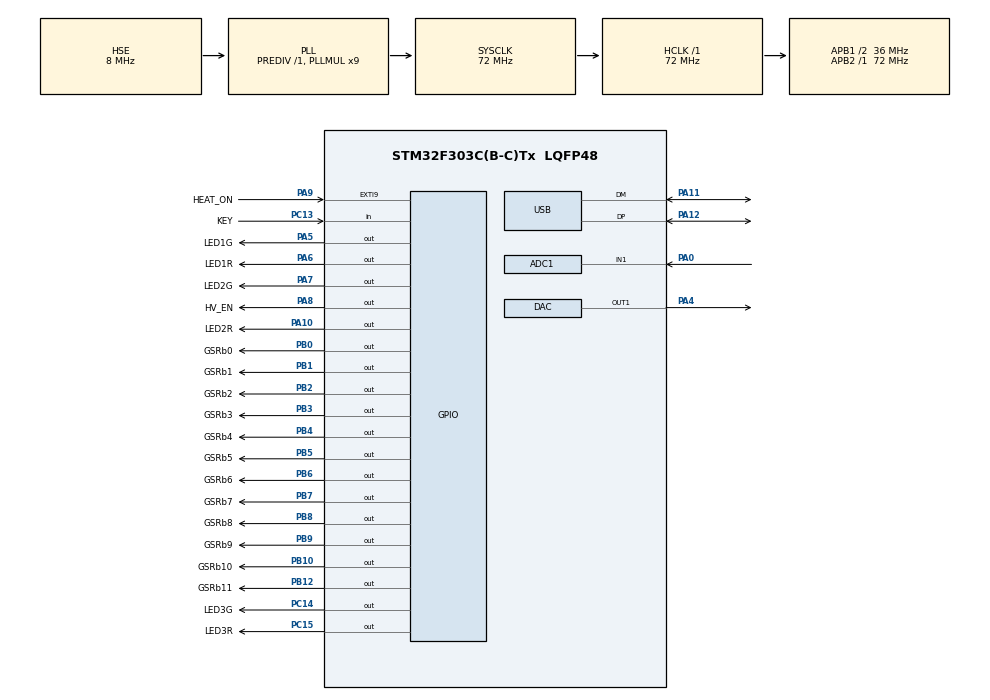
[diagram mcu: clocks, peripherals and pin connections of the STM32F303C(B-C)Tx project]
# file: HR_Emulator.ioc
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ADC1.Channel-0\#ChannelRegularConversion=ADC_CHANNEL_1
ADC1.NbrOfConversionFlag=1
ADC1.Offset-0\#ChannelRegularConversion=0
ADC1.OffsetNumber-0\#ChannelRegularConversion=ADC_OFFSET_NONE
ADC1.Rank-0\#ChannelRegularConversion=1
ADC1.SamplingTime-0\#ChannelRegularConversion=ADC_SAMPLETIME_1CYCLE_5
ADC1.SamplingTimeOPAMP-0\#ChannelRegularConversion=ADC_SAMPLETIME_4CYCLES_5
ADC1.master=1
Mcu.Family=STM32F3
Mcu.Name=STM32F303C(B-C)Tx
Mcu.Package=LQFP48
NVIC.PriorityGroup=NVIC_PRIORITYGROUP_4
PA0.Mode=IN1-Single-Ended
PA0.Signal=ADC1_IN1
PA10.GPIO_Label=LED2R
PA10.Signal=GPIO_Output
PA11.Mode=Device
PA11.Signal=USB_DM
PA12.Mode=Device
PA12.Signal=USB_DP
PA13.Mode=Serial_Wire
PA13.Signal=SYS_JTMS-SWDIO
PA14.Mode=Serial_Wire
PA14.Signal=SYS_JTCK-SWCLK
PA4.Signal=COMP_DAC1_group
PA5.GPIO_Label=LED1G
PA5.Signal=GPIO_Output
PA6.GPIO_Label=LED1R
PA6.Signal=GPIO_Output
PA7.GPIO_Label=LED2G
PA7.Signal=GPIO_Output
PA8.GPIO_Label=HV_EN
PA8.Signal=GPIO_Output
PA9.GPIO_Label=HEAT_ON
PA9.Signal=GPXTI9
PB0.GPIO_Label=GSRb0
PB0.Signal=GPIO_Output
PB1.GPIO_Label=GSRb1
PB1.Signal=GPIO_Output
PB10.GPIO_Label=GSRb10
PB10.Signal=GPIO_Output
PB12.GPIO_Label=GSRb11
PB12.Signal=GPIO_Output
PB2.GPIO_Label=GSRb2
PB2.Signal=GPIO_Output
PB3.GPIO_Label=GSRb3
PB3.Signal=GPIO_Output
PB4.GPIO_Label=GSRb4
PB4.Signal=GPIO_Output
PB5.GPIO_Label=GSRb5
PB5.Signal=GPIO_Output
PB6.GPIO_Label=GSRb6
PB6.Signal=GPIO_Output
PB7.GPIO_Label=GSRb7
PB7.Signal=GPIO_Output
PB8.GPIO_Label=GSRb8
PB8.Signal=GPIO_Output
PB9.GPIO_Label=GSRb9
PB9.Signal=GPIO_Output
PC13.GPIO_Label=KEY
PC13.Signal=GPIO_Input
PC14-OSC32_IN.GPIO_Label=LED3G
PC14-OSC32_IN.Signal=GPIO_Output
PC15-OSC32_OUT.GPIO_Label=LED3R
PC15-OSC32_OUT.Signal=GPIO_Output
PF0-OSC_IN.Mode=HSE-External-Oscillator
PF0-OSC_IN.Signal=RCC_OSC_IN
PF1-OSC_OUT.Mode=HSE-External-Oscillator
PF1-OSC_OUT.Signal=RCC_OSC_OUT
ProjectManager.HeapSize=0x200
ProjectManager.StackSize=0x400
ProjectManager.TargetToolchain=MDK-ARM V5.32
RCC.AHBFreq_Value=72000000
RCC.APB1CLKDivider=RCC_HCLK_DIV2
RCC.APB1Freq_Value=36000000
RCC.APB1TimFreq_Value=72000000
RCC.APB2Freq_Value=72000000
RCC.APB2TimFreq_Value=72000000
RCC.CortexFreq_Value=72000000
RCC.HCLKFreq_Value=72000000
RCC.HSE_VALUE=8000000
RCC.HSI_VALUE=8000000
RCC.LSE_VALUE=32768
RCC.PLLMUL=RCC_PLL_MUL9
RCC.PRESCALERUSB=RCC_USBCLKSOURCE_PLL_DIV1_5
RCC.SYSCLKFreq_VALUE=72000000
RCC.SYSCLKSourceVirtual=RCC_SYSCLKSOURCE_PLLCLK
RCC.USBFreq_Value=48000000
SH.COMP_DAC1_group.0=DAC_OUT1,DAC_OUT1
USB.low_power_enable=DISABLE
USB.lpm_enable=DISABLE
board=custom

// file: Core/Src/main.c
/* USER CODE BEGIN Header */
/**
  ******************************************************************************
  * @file           : main.c
  * @brief          : Main program body
  ******************************************************************************
  * @attention
  *
  * Copyright (c) 2026 STMicroelectronics.
  * All rights reserved.
  *
  * This software is licensed under terms that can be found in the LICENSE file
  * in the root directory of this software component.
  * If no LICENSE file comes with this software, it is provided AS-IS.
  *
  ******************************************************************************
  */
/* USER CODE END Header */
#include "main.h"
#include "adc.h"
#include "dac.h"
#include "usb.h"
#include "gpio.h"

/* USER CODE BEGIN Includes */
#include "usbd_vendor.h"
#include "led.h"
#include "btn.h"
#include "messages.h"
/* USER CODE END Includes */

void SystemClock_Config(void);

int main(void)
{

  /* MCU Configuration--------------------------------------------------------*/

  /* Reset of all peripherals, Initializes the Flash interface and the Systick. */
  HAL_Init();

  /* Configure the system clock */
  SystemClock_Config();

  /* Initialize all configured peripherals */
  MX_GPIO_Init();
  MX_ADC1_Init();
  MX_DAC_Init();
  MX_USB_PCD_Init();
  /* USER CODE BEGIN 2 */
  Message_Init();
  USBDV_Init();   /* vendor USB: WinUSB auto-bind, enumeration only */
  LED_Init();
  BTN_Init();
  /* USER CODE END 2 */

  /* Infinite loop */
  while (1)
  {

    /* USER CODE BEGIN 3 */
    LED_Task();
    BTN_Task();
    Message_Poll();
  }
  /* USER CODE END 3 */
}

void SystemClock_Config(void)
{
  RCC_OscInitTypeDef RCC_OscInitStruct = {0};
  RCC_ClkInitTypeDef RCC_ClkInitStruct = {0};
  RCC_PeriphCLKInitTypeDef PeriphClkInit = {0};

  /** Initializes the RCC Oscillators according to the specified parameters
  * in the RCC_OscInitTypeDef structure.
  */
  RCC_OscInitStruct.OscillatorType = RCC_OSCILLATORTYPE_HSE;
  RCC_OscInitStruct.HSEState = RCC_HSE_ON;
  RCC_OscInitStruct.HSEPredivValue = RCC_HSE_PREDIV_DIV1;
  RCC_OscInitStruct.HSIState = RCC_HSI_ON;
  RCC_OscInitStruct.PLL.PLLState = RCC_PLL_ON;
  RCC_OscInitStruct.PLL.PLLSource = RCC_PLLSOURCE_HSE;
  RCC_OscInitStruct.PLL.PLLMUL = RCC_PLL_MUL9;
  if (HAL_RCC_OscConfig(&RCC_OscInitStruct) != HAL_OK)
  {
    Error_Handler();
  }

  /** Initializes the CPU, AHB and APB buses clocks
  */
  RCC_ClkInitStruct.ClockType = RCC_CLOCKTYPE_HCLK|RCC_CLOCKTYPE_SYSCLK
                              |RCC_CLOCKTYPE_PCLK1|RCC_CLOCKTYPE_PCLK2;
  RCC_ClkInitStruct.SYSCLKSource = RCC_SYSCLKSOURCE_PLLCLK;
  RCC_ClkInitStruct.AHBCLKDivider = RCC_SYSCLK_DIV1;
  RCC_ClkInitStruct.APB1CLKDivider = RCC_HCLK_DIV2;
  RCC_ClkInitStruct.APB2CLKDivider = RCC_HCLK_DIV1;

  if (HAL_RCC_ClockConfig(&RCC_ClkInitStruct, FLASH_LATENCY_2) != HAL_OK)
  {
    Error_Handler();
  }
  PeriphClkInit.PeriphClockSelection = RCC_PERIPHCLK_USB|RCC_PERIPHCLK_ADC12;
  PeriphClkInit.Adc12ClockSelection = RCC_ADC12PLLCLK_DIV1;
  PeriphClkInit.USBClockSelection = RCC_USBCLKSOURCE_PLL_DIV1_5;
  if (HAL_RCCEx_PeriphCLKConfig(&PeriphClkInit) != HAL_OK)
  {
    Error_Handler();
  }
}

void Error_Handler(void)
{
  __disable_irq();
  while (1)
  {
  }
}
